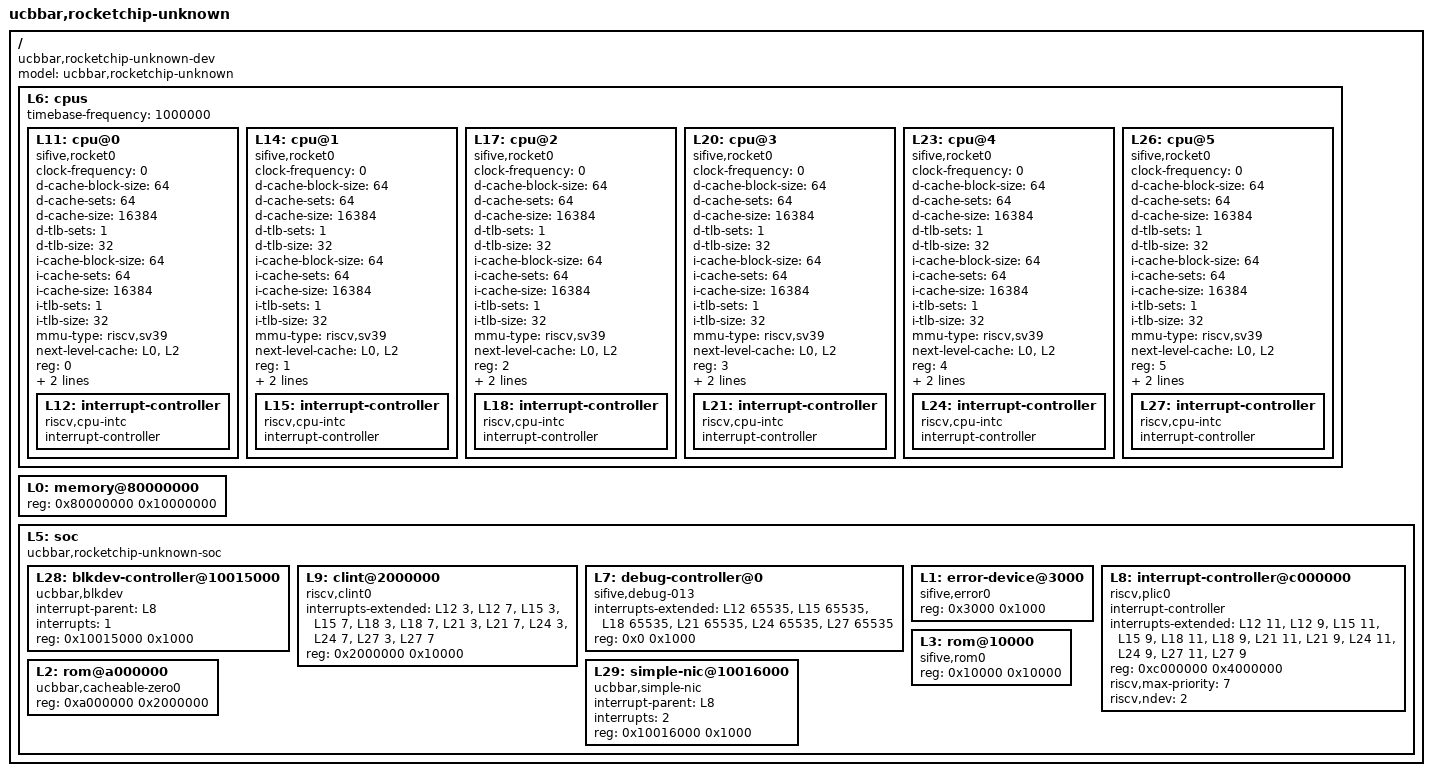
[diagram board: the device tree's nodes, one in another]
/dts-v1/;

/ {
        #address-cells = <1>;
        #size-cells = <1>;
        compatible = "ucbbar,rocketchip-unknown-dev";
        model = "ucbbar,rocketchip-unknown";
        L6: cpus {
                #address-cells = <1>;
                #size-cells = <0>;
                timebase-frequency = <1000000>;
                L11: cpu@0 {
                        clock-frequency = <0>;
                        compatible = "sifive,rocket0", "riscv";
                        d-cache-block-size = <64>;
                        d-cache-sets = <64>;
                        d-cache-size = <16384>;
                        d-tlb-sets = <1>;
                        d-tlb-size = <32>;
                        device_type = "cpu";
                        i-cache-block-size = <64>;
                        i-cache-sets = <64>;
                        i-cache-size = <16384>;
                        i-tlb-sets = <1>;
                        i-tlb-size = <32>;
                        mmu-type = "riscv,sv39";
                        next-level-cache = <&L0 &L2>;
                        reg = <0>;
                        riscv,isa = "rv64imafdc";
                        status = "okay";
                        tlb-split;
                        L12: interrupt-controller {
                                #interrupt-cells = <1>;
                                compatible = "riscv,cpu-intc";
                                interrupt-controller;
                        };
                };
                L14: cpu@1 {
                        clock-frequency = <0>;
                        compatible = "sifive,rocket0", "riscv";
                        d-cache-block-size = <64>;
                        d-cache-sets = <64>;
                        d-cache-size = <16384>;
                        d-tlb-sets = <1>;
                        d-tlb-size = <32>;
                        device_type = "cpu";
                        i-cache-block-size = <64>;
                        i-cache-sets = <64>;
                        i-cache-size = <16384>;
                        i-tlb-sets = <1>;
                        i-tlb-size = <32>;
                        mmu-type = "riscv,sv39";
                        next-level-cache = <&L0 &L2>;
                        reg = <1>;
                        riscv,isa = "rv64imafdc";
                        status = "okay";
                        tlb-split;
                        L15: interrupt-controller {
                                #interrupt-cells = <1>;
                                compatible = "riscv,cpu-intc";
                                interrupt-controller;
                        };
                };
                L17: cpu@2 {
                        clock-frequency = <0>;
                        compatible = "sifive,rocket0", "riscv";
                        d-cache-block-size = <64>;
                        d-cache-sets = <64>;
                        d-cache-size = <16384>;
                        d-tlb-sets = <1>;
                        d-tlb-size = <32>;
                        device_type = "cpu";
                        i-cache-block-size = <64>;
                        i-cache-sets = <64>;
                        i-cache-size = <16384>;
                        i-tlb-sets = <1>;
                        i-tlb-size = <32>;
                        mmu-type = "riscv,sv39";
                        next-level-cache = <&L0 &L2>;
                        reg = <2>;
                        riscv,isa = "rv64imafdc";
                        status = "okay";
                        tlb-split;
                        L18: interrupt-controller {
                                #interrupt-cells = <1>;
                                compatible = "riscv,cpu-intc";
                                interrupt-controller;
                        };
                };
                L20: cpu@3 {
                        clock-frequency = <0>;
                        compatible = "sifive,rocket0", "riscv";
                        d-cache-block-size = <64>;
                        d-cache-sets = <64>;
                        d-cache-size = <16384>;
                        d-tlb-sets = <1>;
                        d-tlb-size = <32>;
                        device_type = "cpu";
                        i-cache-block-size = <64>;
                        i-cache-sets = <64>;
                        i-cache-size = <16384>;
                        i-tlb-sets = <1>;
                        i-tlb-size = <32>;
                        mmu-type = "riscv,sv39";
                        next-level-cache = <&L0 &L2>;
                        reg = <3>;
                        riscv,isa = "rv64imafdc";
                        status = "okay";
                        tlb-split;
                        L21: interrupt-controller {
                                #interrupt-cells = <1>;
                                compatible = "riscv,cpu-intc";
                                interrupt-controller;
                        };
                };
                L23: cpu@4 {
                        clock-frequency = <0>;
                        compatible = "sifive,rocket0", "riscv";
                        d-cache-block-size = <64>;
                        d-cache-sets = <64>;
                        d-cache-size = <16384>;
                        d-tlb-sets = <1>;
                        d-tlb-size = <32>;
                        device_type = "cpu";
                        i-cache-block-size = <64>;
                        i-cache-sets = <64>;
                        i-cache-size = <16384>;
                        i-tlb-sets = <1>;
                        i-tlb-size = <32>;
                        mmu-type = "riscv,sv39";
                        next-level-cache = <&L0 &L2>;
                        reg = <4>;
                        riscv,isa = "rv64imafdc";
                        status = "okay";
                        tlb-split;
                        L24: interrupt-controller {
                                #interrupt-cells = <1>;
                                compatible = "riscv,cpu-intc";
                                interrupt-controller;
                        };
                };
                L26: cpu@5 {
                        clock-frequency = <0>;
                        compatible = "sifive,rocket0", "riscv";
                        d-cache-block-size = <64>;
                        d-cache-sets = <64>;
                        d-cache-size = <16384>;
                        d-tlb-sets = <1>;
                        d-tlb-size = <32>;
                        device_type = "cpu";
                        i-cache-block-size = <64>;
                        i-cache-sets = <64>;
                        i-cache-size = <16384>;
                        i-tlb-sets = <1>;
                        i-tlb-size = <32>;
                        mmu-type = "riscv,sv39";
                        next-level-cache = <&L0 &L2>;
                        reg = <5>;
                        riscv,isa = "rv64imafdc";
                        status = "okay";
                        tlb-split;
                        L27: interrupt-controller {
                                #interrupt-cells = <1>;
                                compatible = "riscv,cpu-intc";
                                interrupt-controller;
                        };
                };
        };
        L0: memory@80000000 {
                device_type = "memory";
                reg = <0x80000000 0x10000000>;
        };
        L5: soc {
                #address-cells = <1>;
                #size-cells = <1>;
                compatible = "ucbbar,rocketchip-unknown-soc", "simple-bus";
                ranges;
                L28: blkdev-controller@10015000 {
                        compatible = "ucbbar,blkdev";
                        interrupt-parent = <&L8>;
                        interrupts = <1>;
                        reg = <0x10015000 0x1000>;
                        reg-names = "control";
                };
                L9: clint@2000000 {
                        compatible = "riscv,clint0";
                        interrupts-extended = <&L12 3 &L12 7 &L15 3 &L15 7 &L18 3 &L18 7 &L21 3 &L21 7 &L24 3 &L24 7 &L27 3 &L27 7>;
                        reg = <0x2000000 0x10000>;
                        reg-names = "control";
                };
                L7: debug-controller@0 {
                        compatible = "sifive,debug-013", "riscv,debug-013";
                        interrupts-extended = <&L12 65535 &L15 65535 &L18 65535 &L21 65535 &L24 65535 &L27 65535>;
                        reg = <0x0 0x1000>;
                        reg-names = "control";
                };
                L1: error-device@3000 {
                        compatible = "sifive,error0";
                        reg = <0x3000 0x1000>;
                        reg-names = "mem";
                };
                L8: interrupt-controller@c000000 {
                        #interrupt-cells = <1>;
                        compatible = "riscv,plic0";
                        interrupt-controller;
                        interrupts-extended = <&L12 11 &L12 9 &L15 11 &L15 9 &L18 11 &L18 9 &L21 11 &L21 9 &L24 11 &L24 9 &L27 11 &L27 9>;
                        reg = <0xc000000 0x4000000>;
                        reg-names = "control";
                        riscv,max-priority = <7>;
                        riscv,ndev = <2>;
                };
                L3: rom@10000 {
                        compatible = "sifive,rom0";
                        reg = <0x10000 0x10000>;
                        reg-names = "mem";
                };
                L2: rom@a000000 {
                        compatible = "ucbbar,cacheable-zero0";
                        reg = <0xa000000 0x2000000>;
                        reg-names = "mem";
                };
                L29: simple-nic@10016000 {
                        compatible = "ucbbar,simple-nic";
                        interrupt-parent = <&L8>;
                        interrupts = <2>;
                        reg = <0x10016000 0x1000>;
                        reg-names = "control";
                };
        };
};
